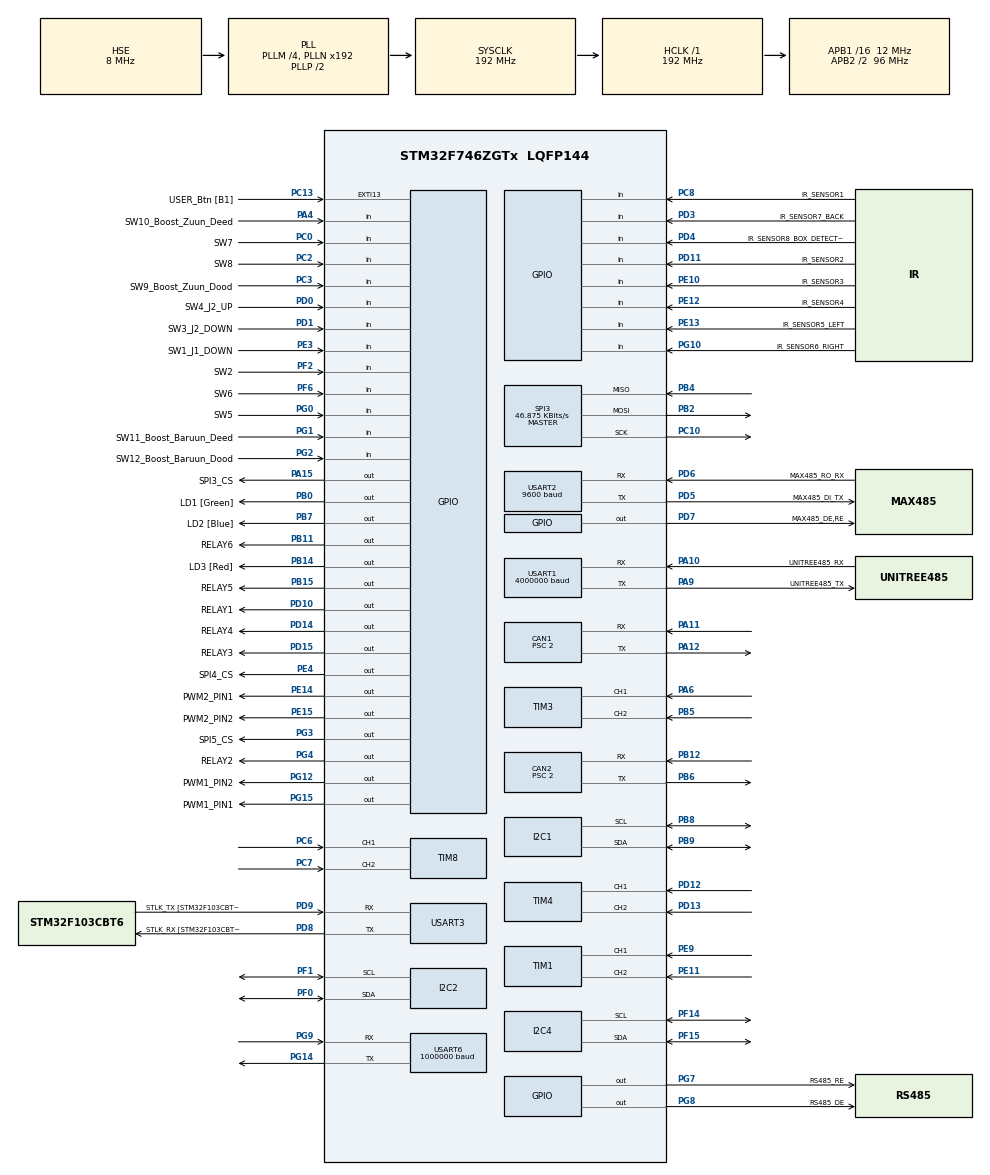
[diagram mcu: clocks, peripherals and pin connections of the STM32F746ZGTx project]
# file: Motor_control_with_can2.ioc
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CAN1.ABOM=ENABLE
CAN1.BS1=CAN_BS1_4TQ
CAN1.CalculateBaudRate=1000000
CAN1.CalculateTimeBit=1000
CAN1.CalculateTimeQuantum=166.66666666666666
CAN1.NART=ENABLE
CAN1.Prescaler=2
CAN2.ABOM=ENABLE
CAN2.BS1=CAN_BS1_4TQ
CAN2.CalculateBaudRate=1000000
CAN2.CalculateTimeBit=1000
CAN2.CalculateTimeQuantum=166.66666666666666
CAN2.NART=ENABLE
CAN2.Prescaler=2
Dma.Request0=USART2_TX
Dma.Request1=USART6_RX
Dma.Request2=USART6_TX
Dma.USART2_TX.0.Direction=DMA_MEMORY_TO_PERIPH
Dma.USART2_TX.0.FIFOMode=DMA_FIFOMODE_DISABLE
Dma.USART2_TX.0.Instance=DMA1_Stream6
Dma.USART2_TX.0.MemDataAlignment=DMA_MDATAALIGN_BYTE
Dma.USART2_TX.0.MemInc=DMA_MINC_ENABLE
Dma.USART2_TX.0.Mode=DMA_CIRCULAR
Dma.USART2_TX.0.PeriphDataAlignment=DMA_PDATAALIGN_BYTE
Dma.USART2_TX.0.PeriphInc=DMA_PINC_DISABLE
Dma.USART2_TX.0.Priority=DMA_PRIORITY_VERY_HIGH
Dma.USART6_RX.1.Direction=DMA_PERIPH_TO_MEMORY
Dma.USART6_RX.1.FIFOMode=DMA_FIFOMODE_DISABLE
Dma.USART6_RX.1.Instance=DMA2_Stream1
Dma.USART6_RX.1.MemDataAlignment=DMA_MDATAALIGN_BYTE
Dma.USART6_RX.1.MemInc=DMA_MINC_ENABLE
Dma.USART6_RX.1.Mode=DMA_NORMAL
Dma.USART6_RX.1.PeriphDataAlignment=DMA_PDATAALIGN_BYTE
Dma.USART6_RX.1.PeriphInc=DMA_PINC_DISABLE
Dma.USART6_RX.1.Priority=DMA_PRIORITY_VERY_HIGH
Dma.USART6_TX.2.Direction=DMA_MEMORY_TO_PERIPH
Dma.USART6_TX.2.FIFOMode=DMA_FIFOMODE_DISABLE
Dma.USART6_TX.2.Instance=DMA2_Stream6
Dma.USART6_TX.2.MemDataAlignment=DMA_MDATAALIGN_BYTE
Dma.USART6_TX.2.MemInc=DMA_MINC_ENABLE
Dma.USART6_TX.2.Mode=DMA_CIRCULAR
Dma.USART6_TX.2.PeriphDataAlignment=DMA_PDATAALIGN_BYTE
Dma.USART6_TX.2.PeriphInc=DMA_PINC_DISABLE
Dma.USART6_TX.2.Priority=DMA_PRIORITY_VERY_HIGH
I2C1.Timing=0x40000A0B
I2C2.Timing=0x40000A0B
I2C4.Timing=0x40000A0B
Mcu.Family=STM32F7
Mcu.Name=STM32F746ZGTx
Mcu.Package=LQFP144
NVIC.CAN1_RX0_IRQn=true\:0\:0\:false\:false\:true\:true\:true\:true
NVIC.CAN1_RX1_IRQn=true\:0\:0\:false\:false\:true\:true\:true\:true
NVIC.CAN2_RX0_IRQn=true\:0\:0\:false\:false\:true\:true\:true\:true
NVIC.CAN2_RX1_IRQn=true\:0\:0\:false\:false\:true\:true\:true\:true
NVIC.DMA1_Stream6_IRQn=true\:0\:0\:false\:false\:true\:false\:true\:true
NVIC.DMA2_Stream1_IRQn=true\:0\:0\:false\:false\:true\:false\:true\:true
NVIC.DMA2_Stream6_IRQn=true\:0\:0\:false\:false\:true\:false\:true\:true
NVIC.PriorityGroup=NVIC_PRIORITYGROUP_4
NVIC.TIM7_IRQn=true\:15\:0\:true\:false\:true\:false\:true\:true
NVIC.TimeBase=TIM7_IRQn
NVIC.TimeBaseIP=TIM7
NVIC.USART2_IRQn=true\:0\:0\:false\:false\:true\:true\:true\:true
NVIC.USART6_IRQn=true\:0\:0\:false\:false\:true\:true\:true\:true
PA10.GPIO_Label=UNITREE485_RX
PA10.Mode=Asynchronous
PA10.Signal=USART1_RX
PA11.Mode=CAN_Activate
PA11.Signal=CAN1_RX
PA12.Mode=CAN_Activate
PA12.Signal=CAN1_TX
PA13.GPIO_Label=TMS
PA13.Mode=Serial_Wire
PA13.Signal=SYS_JTMS-SWDIO
PA14.GPIO_Label=TCK
PA14.Mode=Serial_Wire
PA14.Signal=SYS_JTCK-SWCLK
PA15.GPIO_Label=SPI3_CS
PA15.GPIO_Speed=GPIO_SPEED_FREQ_LOW
PA15.Signal=GPIO_Output
PA4.GPIO_Label=SW10_Boost_Zuun_Deed
PA4.Signal=GPIO_Input
PA6.Signal=S_TIM3_CH1
PA9.GPIO_Label=UNITREE485_TX
PA9.Mode=Asynchronous
PA9.Signal=USART1_TX
PB0.GPIO_Label=LD1 [Green]
PB0.Signal=GPIO_Output
PB11.GPIO_Label=RELAY6
PB11.Signal=GPIO_Output
PB12.Mode=CAN_Activate
PB12.Signal=CAN2_RX
PB14.GPIO_Label=LD3 [Red]
PB14.Signal=GPIO_Output
PB15.GPIO_Label=RELAY5
PB15.Signal=GPIO_Output
PB2.Mode=Full_Duplex_Master
PB2.Signal=SPI3_MOSI
PB4.Mode=Full_Duplex_Master
PB4.Signal=SPI3_MISO
PB5.Signal=S_TIM3_CH2
PB6.Mode=CAN_Activate
PB6.Signal=CAN2_TX
PB7.GPIO_Label=LD2 [Blue]
PB7.Signal=GPIO_Output
PB8.Mode=I2C
PB8.Signal=I2C1_SCL
PB9.Mode=I2C
PB9.Signal=I2C1_SDA
PC0.GPIO_Label=SW7
PC0.Signal=GPIO_Input
PC10.Mode=Full_Duplex_Master
PC10.Signal=SPI3_SCK
PC13.GPIO_Label=USER_Btn [B1]
PC13.Signal=GPXTI13
PC14/OSC32_IN.Mode=LSE-External-Oscillator
PC14/OSC32_IN.Signal=RCC_OSC32_IN
PC15/OSC32_OUT.Mode=LSE-External-Oscillator
PC15/OSC32_OUT.Signal=RCC_OSC32_OUT
PC2.GPIO_Label=SW8
PC2.Signal=GPIO_Input
PC3.GPIO_Label=SW9_Boost_Zuun_Dood
PC3.Signal=GPIO_Input
PC6.Signal=S_TIM8_CH1
PC7.Signal=S_TIM8_CH2
PC8.GPIO_Label=IR_SENSOR1
PC8.Signal=GPIO_Input
PD0.GPIO_Label=SW4_J2_UP
PD0.Signal=GPIO_Input
PD1.GPIO_Label=SW3_J2_DOWN
PD1.Signal=GPIO_Input
PD10.GPIO_Label=RELAY1
PD10.Signal=GPIO_Output
PD11.GPIO_Label=IR_SENSOR2
PD11.Signal=GPIO_Input
PD12.Signal=S_TIM4_CH1
PD13.Signal=S_TIM4_CH2
PD14.GPIO_Label=RELAY4
PD14.Signal=GPIO_Output
PD15.GPIO_Label=RELAY3
PD15.Signal=GPIO_Output
PD3.GPIO_Label=IR_SENSOR7_BACK
PD3.Signal=GPIO_Input
PD4.GPIO_Label=IR_SENSOR8_BOX_DETECTION
PD4.Signal=GPIO_Input
PD5.GPIO_Label=MAX485_DI_TX
PD5.Mode=Asynchronous
PD5.Signal=USART2_TX
PD6.GPIO_Label=MAX485_RO_RX
PD6.Mode=Asynchronous
PD6.Signal=USART2_RX
PD7.GPIO_Label=MAX485_DE,RE
PD7.Signal=GPIO_Output
PD8.GPIO_Label=STLK_RX [STM32F103CBT6_PA3]
PD8.GPIO_PuPd=GPIO_PULLUP
PD8.Mode=Asynchronous
PD8.Signal=USART3_TX
PD9.GPIO_Label=STLK_TX [STM32F103CBT6_PA2]
PD9.GPIO_PuPd=GPIO_PULLUP
PD9.Mode=Asynchronous
PD9.Signal=USART3_RX
PE10.GPIO_Label=IR_SENSOR3
PE10.Signal=GPIO_Input
PE11.Signal=S_TIM1_CH2
PE12.GPIO_Label=IR_SENSOR4
PE12.Signal=GPIO_Input
PE13.GPIO_Label=IR_SENSOR5_LEFT
PE13.Signal=GPIO_Input
PE14.GPIO_Label=PWM2_PIN1
PE14.Signal=GPIO_Output
PE15.GPIO_Label=PWM2_PIN2
PE15.Signal=GPIO_Output
PE3.GPIO_Label=SW1_J1_DOWN
PE3.Signal=GPIO_Input
PE4.GPIO_Label=SPI4_CS
PE4.Signal=GPIO_Output
PE7.Signal=UART7_RX
PE9.Signal=S_TIM1_CH1
PF0.Mode=I2C
PF0.Signal=I2C2_SDA
PF1.Mode=I2C
PF1.Signal=I2C2_SCL
PF14.Mode=I2C
PF14.Signal=I2C4_SCL
PF15.Mode=I2C
PF15.Signal=I2C4_SDA
PF2.GPIO_Label=SW2
PF2.Signal=GPIO_Input
PF6.GPIO_Label=SW6
PF6.Signal=GPIO_Input
PG0.GPIO_Label=SW5
PG0.Signal=GPIO_Input
PG1.GPIO_Label=SW11_Boost_Baruun_Deed
PG1.Signal=GPIO_Input
PG10.GPIO_Label=IR_SENSOR6_RIGHT
PG10.Signal=GPIO_Input
PG12.GPIO_Label=PWM1_PIN2
PG12.Signal=GPIO_Output
PG14.Mode=Asynchronous
PG14.Signal=USART6_TX
PG15.GPIO_Label=PWM1_PIN1
PG15.Signal=GPIO_Output
PG2.GPIO_Label=SW12_Boost_Baruun_Dood
PG2.Signal=GPIO_Input
PG3.GPIO_Label=SPI5_CS
PG3.Signal=GPIO_Output
PG4.GPIO_Label=RELAY2
PG4.Signal=GPIO_Output
PG7.GPIO_Label=RS485_RE
PG7.GPIO_Speed=GPIO_SPEED_FREQ_VERY_HIGH
PG7.PinState=GPIO_PIN_SET
PG7.Signal=GPIO_Output
PG8.GPIO_Label=RS485_DE
PG8.GPIO_Speed=GPIO_SPEED_FREQ_VERY_HIGH
PG8.Signal=GPIO_Output
PG9.Mode=Asynchronous
PG9.Signal=USART6_RX
PH0/OSC_IN.GPIO_Label=MCO [STM32F103CBT6_PA8]
PH0/OSC_IN.Mode=HSE-External-Oscillator
PH0/OSC_IN.Signal=RCC_OSC_IN
PH1/OSC_OUT.Mode=HSE-External-Oscillator
PH1/OSC_OUT.Signal=RCC_OSC_OUT
ProjectManager.HeapSize=0x200
ProjectManager.StackSize=0x400
ProjectManager.TargetToolchain=STM32CubeIDE
RCC.48MHZClocksFreq_Value=24000000
RCC.AHBFreq_Value=192000000
RCC.APB1CLKDivider=RCC_HCLK_DIV16
RCC.APB1Freq_Value=12000000
RCC.APB1TimFreq_Value=24000000
RCC.APB2CLKDivider=RCC_HCLK_DIV2
RCC.APB2Freq_Value=96000000
RCC.APB2TimFreq_Value=192000000
RCC.CortexFreq_Value=192000000
RCC.HCLKFreq_Value=192000000
RCC.HSE_VALUE=8000000
RCC.HSI_VALUE=16000000
RCC.PLLM=4
RCC.PLLMUL=RCC_PLL_MUL9
RCC.PLLQ=3
RCC.PLLSourceVirtual=RCC_PLLSOURCE_HSE
RCC.PRESCALERUSB=RCC_USBCLKSOURCE_PLL_DIV1_5
RCC.SYSCLKFreq_VALUE=192000000
RCC.SYSCLKSource=RCC_SYSCLKSOURCE_PLLCLK
RCC.SYSCLKSourceVirtual=RCC_SYSCLKSOURCE_PLLCLK
RCC.USART1CLockSelection=RCC_USART1CLKSOURCE_SYSCLK
RCC.USBFreq_Value=128000000
RCC.VCOOutputFreq_Value=384000000
SH.S_TIM1_CH1.0=TIM1_CH1,Encoder_Interface
SH.S_TIM1_CH2.0=TIM1_CH2,Encoder_Interface
SH.S_TIM3_CH1.0=TIM3_CH1,Encoder_Interface
SH.S_TIM3_CH2.0=TIM3_CH2,Encoder_Interface
SH.S_TIM4_CH1.0=TIM4_CH1,Encoder_Interface
SH.S_TIM4_CH2.0=TIM4_CH2,Encoder_Interface
SH.S_TIM8_CH1.0=TIM8_CH1,Encoder_Interface
SH.S_TIM8_CH2.0=TIM8_CH2,Encoder_Interface
SPI3.BaudRatePrescaler=SPI_BAUDRATEPRESCALER_256
SPI3.CLKPhase=SPI_PHASE_2EDGE
SPI3.CLKPolarity=SPI_POLARITY_HIGH
SPI3.CalculateBaudRate=46.875 KBits/s
SPI3.DataSize=SPI_DATASIZE_8BIT
SPI3.Direction=SPI_DIRECTION_2LINES
SPI3.FirstBit=SPI_FIRSTBIT_LSB
SPI3.Mode=SPI_MODE_MASTER
SPI3.VirtualType=VM_MASTER
TIM3.EncoderMode=TIM_ENCODERMODE_TI12
TIM4.EncoderMode=TIM_ENCODERMODE_TI12
TIM8.CounterMode=TIM_COUNTERMODE_UP
TIM8.IC1Polarity=TIM_ICPOLARITY_RISING
USART1.BaudRate=4000000
USART1.VirtualMode-Asynchronous=VM_ASYNC
USART2.BaudRate=9600
USART2.VirtualMode-Asynchronous=VM_ASYNC
USART3.VirtualMode-Asynchronous=VM_ASYNC
USART6.BaudRate=1000000
USART6.VirtualMode-Asynchronous=VM_ASYNC
VP_SYS_VS_tim7.Mode=TIM7
board=NUCLEO-F746ZG

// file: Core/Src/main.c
/* USER CODE BEGIN Header */
/**
 ******************************************************************************
 * @file           : main.c
 * @brief          : Main program body
 ******************************************************************************
 * @attention
 *
 * Copyright (c) 2026 STMicroelectronics.
 * All rights reserved.
 *
 * This software is licensed under terms that can be found in the LICENSE file
 * in the root directory of this software component.
 * If no LICENSE file comes with this software, it is provided AS-IS.
 *
 ******************************************************************************
 */
/* USER CODE END Header */
#include "main.h"

/* USER CODE BEGIN Includes */
#include "stdio.h"
#include "robstride.h"
#include "motor_control.h"
#include "WEncoder_CAN.h"

/* USER CODE END Includes */

CAN_HandleTypeDef hcan1;
CAN_HandleTypeDef hcan2;

I2C_HandleTypeDef hi2c1;
I2C_HandleTypeDef hi2c2;
I2C_HandleTypeDef hi2c4;

SPI_HandleTypeDef hspi3;

TIM_HandleTypeDef htim1;
TIM_HandleTypeDef htim3;
TIM_HandleTypeDef htim4;
TIM_HandleTypeDef htim8;

UART_HandleTypeDef huart1;
UART_HandleTypeDef huart2;
UART_HandleTypeDef huart3;
UART_HandleTypeDef huart6;
DMA_HandleTypeDef hdma_usart2_tx;
DMA_HandleTypeDef hdma_usart6_rx;
DMA_HandleTypeDef hdma_usart6_tx;

/* USER CODE BEGIN PV */

volatile uint32_t g_live_cmd   = 0U;
volatile uint32_t g_live_apply = 0U;
volatile uint8_t  brake_status = 0x00U;

static RobStrideMotor *motor_brake = NULL;   /* motor0, CAN ID 0x01 */
static RobStrideMotor *motor_acc   = NULL;   /* motor1, CAN ID 0x02 */
MOTOR_send Steering_motor_cmd;
MOTOR_recv Steering_motor_fdbck;
MOTOR_send Lift_motor_cmd;
MOTOR_recv Lift_motor_fdbck;

/* ── Joystick ─────────────────────────────────────────────────────────────
 * RX[6] → brake motor   (0=min … 127=center … 255=max)
 * RX[8] → acc motor     (0=min … 127=center … 255=max)
 * ──────────────────────────────────────────────────────────────────────── */
#define JOY_CENTER          (127U)
#define JOY_DEADBAND        (10U)        /* ±10 дотор хөдлөхгүй */

#define BRAKE_POS_RELEASED  (4.00f)
#define BRAKE_POS_ENGAGED   (6.33f)
#define ACC_POS_RELEASED    (0.63f)
#define ACC_POS_ENGAGED     (-1.05f)
#define JOY_AXIS            RX[6]
#define STEER_MAX_POS    15.0f   // моторынхоо max position-д тохируул
#define STEER_MIN_POS   -15.0f
#define JOY_STEER       RX[7]
float pos=0.6;

/* ── Briter Wire Encoder тохиргоо ──────────────────────────────────────────
 *  Encoder 0 (index 0): CAN ID=0x01, range=500mm  (50cm)
 *  Encoder 1 (index 1): CAN ID=0x02, range=4000mm (400cm)
 * ────────────────────────────────────────────────────────────────────────── */
#define ENC0_CAN_ID        0x01U
#define ENC0_RESOLUTION_MM 0.0244f   /* BRT38 500mm,  4096PPR */
#define ENC0_TOTAL_COUNTS  20491     /* 500mm / 0.0244mm      */
#define ENC0_MAX_STEP      2000      /* spike filter          */
#define ENC0_LABEL         "Enc50cm"

#define ENC1_CAN_ID        0x02U
#define ENC1_RESOLUTION_MM 0.0610f   /* BRT38 4000mm, 4096PPR */
#define ENC1_TOTAL_COUNTS  65573     /* 4000mm / 0.061mm      */
#define ENC1_MAX_STEP      5000
#define ENC1_LABEL         "Enc400cm"

/* Гаднаас ашиглах глобал утгууд */
float g_enc0_disp_mm = 0.0f;   /* 50cm  encoder displacement */
float g_enc1_disp_mm = 0.0f;   /* 400cm encoder displacement */
/* USER CODE END PV */

void SystemClock_Config(void);
static void MX_GPIO_Init(void);
static void MX_DMA_Init(void);
static void MX_I2C1_Init(void);
static void MX_USART3_UART_Init(void);
static void MX_CAN1_Init(void);
static void MX_I2C2_Init(void);
static void MX_SPI3_Init(void);
static void MX_TIM1_Init(void);
static void MX_TIM3_Init(void);
static void MX_TIM4_Init(void);
static void MX_TIM8_Init(void);
static void MX_USART1_UART_Init(void);
static void MX_USART2_UART_Init(void);
static void MX_I2C4_Init(void);
static void MX_USART6_UART_Init(void);
static void MX_CAN2_Init(void);
/* USER CODE BEGIN PFP */

static void Encoder_CAN2_Init(void);
/* USER CODE END PFP */

/* USER CODE BEGIN 0 */

uint8_t TX[9] = {0x01,0x42, 0x00, 0x00, 0x00, 0x00, 0x00, 0x00, 0x00};
uint8_t  RX[9];

/* printf → UART3 (115200 baud, USB-Serial) */
int __io_putchar(int ch)
{
    uint8_t c = (uint8_t)ch;
    (void)HAL_UART_Transmit(&huart3, &c, 1U, 2U);
    return ch;
}

static void Receive_JoyStick_Data(void)
{
	GPIOA->BSRR = (uint32_t)GPIO_PIN_15 << 16U;
	HAL_SPI_TransmitReceive(&hspi3, TX, RX, 9U, 10U);
	GPIOA->BSRR = GPIO_PIN_15;
}
/**
 * @brief  0–255 joystick утгыг float позиц руу шугаман хөрвүүлэх.
 *         127 = төв (deadband дотор) → pos_center буцаана.
 *         0   = pos_low,  255 = pos_high
 */
/*
 * @brief  0.0–1.0 хэмжилтийг pos_released → pos_engaged хооронд хөрвүүлэх
 */
static float lerp(float t, float from, float to)
{
	return from + t * (to - from);
}

/**
 * @brief  Joystick нэг тэнхлэгийг acc/brake хоёр мотор руу хуваарилах.
 *
 *  raw > center+deadband  →  Acc дарна (t=0→1),  Brake бүрэн тавина
 *  raw < center-deadband  →  Brake дарна (t=0→1), Acc бүрэн тавина
 *  deadband дотор         →  Хоёулан тавина
 */
static void apply_joystick(uint8_t raw)
{
    /* ── Acc / Brake: RX[6] ─────────────────────── */
    float acc_pos, brake_pos;

    if (raw < (JOY_CENTER - JOY_DEADBAND))
    {
        float t = (float)((JOY_CENTER - JOY_DEADBAND) - raw) /
                  (float)(JOY_CENTER - JOY_DEADBAND);
        acc_pos   = lerp(t, ACC_POS_RELEASED, ACC_POS_ENGAGED);
        brake_pos = BRAKE_POS_RELEASED;
    }
    else if (raw > (JOY_CENTER + JOY_DEADBAND))
    {
        float t = (float)(raw - (JOY_CENTER + JOY_DEADBAND)) /
                  (float)(255U - (JOY_CENTER + JOY_DEADBAND));
        brake_pos = lerp(t, BRAKE_POS_RELEASED, BRAKE_POS_ENGAGED);
        acc_pos   = ACC_POS_RELEASED;
    }
    else
    {
        acc_pos   = ACC_POS_RELEASED;
        brake_pos = BRAKE_POS_RELEASED;
    }

    (void)RobStride_WriteFloat(motor_acc,   ROBSTRIDE_IDX_LOC_REF, acc_pos);
    (void)RobStride_WriteFloat(motor_brake, ROBSTRIDE_IDX_LOC_REF, brake_pos);

    /* ── Steering: RX[7] ───────────────────────── */
    int16_t steer_raw = (int16_t)JOY_STEER - 127;

    if (steer_raw > -10 && steer_raw < 10)
    {
        steer_raw = 0;
    }

    float steer_pos = (float)steer_raw * (STEER_MAX_POS / 127.0f);

    Steering_motor_cmd.K_P = 0.1f;
    Steering_motor_cmd.K_W = 0.02f;
    Steering_motor_cmd.Pos = steer_pos;
    SERVO_Send_recv(&Steering_motor_cmd, &Steering_motor_fdbck);
}
static void motor_init(RobStrideMotor *m)
{
	(void)RobStride_ReadParam(m, ROBSTRIDE_IDX_VBUS);   HAL_Delay(50U);
	RobStride_ProcessRx();
	(void)RobStride_EnableActiveReport(m, 10U);          HAL_Delay(50U);
	RobStride_ReadAllParams(m);                          HAL_Delay(50U);
	RobStride_ProcessRx();
	(void)RobStride_Stop(m, 1U);                         HAL_Delay(100U);
	(void)RobStride_WriteU8(m, ROBSTRIDE_IDX_RUN_MODE, ROBSTRIDE_MODE_PP_POS); HAL_Delay(50U);
	(void)RobStride_Enable(m);                           HAL_Delay(100U);
	(void)RobStride_WriteFloat(m, ROBSTRIDE_IDX_LIMIT_TRQ, 15.0f); HAL_Delay(20U);
	(void)RobStride_WriteFloat(m, ROBSTRIDE_IDX_VEL_MAX,   10.0f); HAL_Delay(20U);
	(void)RobStride_WriteFloat(m, ROBSTRIDE_IDX_ACC_SET,    3.0f); HAL_Delay(20U);
}
static void Encoder_CAN2_Init(void)
{
    WEncoder_CAN_Init(&hcan2);

    /* Index 0 — CAN ID 0x01, 500mm (50cm) */
    WEncoder_CAN_AddEncoder(ENC0_CAN_ID, ENC0_LABEL,
                             ENC0_TOTAL_COUNTS, ENC0_RESOLUTION_MM, ENC0_MAX_STEP);

    /* Index 1 — CAN ID 0x02, 4000mm (400cm) */
    WEncoder_CAN_AddEncoder(ENC1_CAN_ID, ENC1_LABEL,
                             ENC1_TOTAL_COUNTS, ENC1_RESOLUTION_MM, ENC1_MAX_STEP);

    if (WEncoder_CAN_FilterStart() != HAL_OK) {
        Error_Handler();
    }
}

/* USER CODE BEGIN 4 */
void HAL_CAN_RxFifo0MsgPendingCallback(CAN_HandleTypeDef *hcan)
{
    if (hcan->Instance == CAN2) {
        WEncoder_CAN_RxCallback(hcan);
    }
}
/* ── Encoder poll + утга шинэчлэх ────────────────────────────────────────── */
static void Encoder_Poll_And_Log(void)
{
    static uint32_t log_at = 0U;
    WEnc_Reading_t enc;

    WEncoder_CAN_Poll();

    /* Encoder 0 — 50cm */
    if (WEncoder_CAN_GetByIndex(0U, &enc) && enc.valid) {
        g_enc0_disp_mm = enc.disp_mm;
    }

    /* Encoder 1 — 400cm */
    if (WEncoder_CAN_GetByIndex(1U, &enc) && enc.valid) {
        g_enc1_disp_mm = enc.disp_mm;
    }

    /* 200ms тутамд UART log */
    if ((HAL_GetTick() - log_at) >= 200U) {
        printf("[ENC0  50cm] disp=%7.2f mm | [ENC1 400cm] disp=%7.2f mm\r\n",
               (double)g_enc0_disp_mm,
               (double)g_enc1_disp_mm);
        log_at = HAL_GetTick();
    }
}
/* USER CODE END 4 */

int main(void)
{
  HAL_Init();
  SystemClock_Config();
  MX_GPIO_Init();
  MX_DMA_Init();
  MX_I2C1_Init();
  MX_USART3_UART_Init();
  MX_CAN1_Init();
  MX_I2C2_Init();
  MX_SPI3_Init();
  MX_TIM1_Init();
  MX_TIM3_Init();
  MX_TIM4_Init();
  MX_TIM8_Init();
  MX_USART1_UART_Init();
  MX_USART2_UART_Init();
  MX_I2C4_Init();
  MX_USART6_UART_Init();
  MX_CAN2_Init();

  /* USER CODE BEGIN 2 */
  Encoder_CAN2_Init();

  Steering_motor_cmd.id  = 1;
  Steering_motor_cmd.mode = 1;
  Lift_motor_cmd.id      = 3;
  Lift_motor_cmd.mode    = 1;
  RobStride_AddMotor(0xFDU, 0x01U);
  RobStride_AddMotor(0xFDU, 0x02U);
  motor_brake = &g_motors[0];
  motor_acc   = &g_motors[1];
  motor_init(motor_brake);
  motor_init(motor_acc);
  (void)RobStride_WriteFloat(motor_brake, ROBSTRIDE_IDX_LOC_REF, BRAKE_POS_RELEASED);
  (void)RobStride_WriteFloat(motor_acc,   ROBSTRIDE_IDX_LOC_REF, ACC_POS_RELEASED);
  HAL_Delay(500U);
  /* USER CODE END 2 */

  while (1)
  {
    /* USER CODE BEGIN 3 */

    /* ── Emergency stop ────────────────────────────────────────────────── */
    if (HAL_GPIO_ReadPin(SW2_GPIO_Port, SW2_Pin) == GPIO_PIN_RESET) {
        (void)RobStride_WriteFloat(motor_brake, ROBSTRIDE_IDX_LOC_REF, BRAKE_POS_ENGAGED);
        (void)RobStride_WriteFloat(motor_acc,   ROBSTRIDE_IDX_LOC_REF, ACC_POS_RELEASED);
        RobStride_ProcessRx();
        Encoder_Poll_And_Log();   /* stop үед ч encoder poll үргэлжилнэ */
        HAL_Delay(10U);
        continue;
    }

    /* ── Lift motor ─────────────────────────────────────────────────────── */
    if (RX[4] == 239) {
        Lift_motor_cmd.K_P = 0.2f; Lift_motor_cmd.Pos = 6.5f;  Lift_motor_cmd.K_W = 0.02f;
        SERVO_Send_recv(&Lift_motor_cmd, &Lift_motor_fdbck);
    } else if (RX[4] == 191) {
        Lift_motor_cmd.K_P = 0.2f; Lift_motor_cmd.Pos = -2.5f; Lift_motor_cmd.K_W = 0.02f;
        SERVO_Send_recv(&Lift_motor_cmd, &Lift_motor_fdbck);
    } else {
        Lift_motor_cmd.K_P = 0.2f; Lift_motor_cmd.Pos = 1.6f;  Lift_motor_cmd.K_W = 0.02f;
        SERVO_Send_recv(&Lift_motor_cmd, &Lift_motor_fdbck);
    }

    /* ── Encoder poll (CAN2) ────────────────────────────────────────────── */
    Encoder_Poll_And_Log();
    /*
     * Энд ашиглах:
     *   g_enc0_disp_mm  — 50cm  encoder displacement (mm)
     *   g_enc1_disp_mm  — 400cm encoder displacement (mm)
     *
     * Жишээ:
     *   if (g_enc0_disp_mm > 300.0f) { ... }   // 30cm хэтэрвэл
     *   if (g_enc1_disp_mm > 2000.0f) { ... }  // 200cm хэтэрвэл
     */

    /* ── Joystick + motors ──────────────────────────────────────────────── */
    Receive_JoyStick_Data();
    apply_joystick(JOY_AXIS);
    RobStride_ProcessRx();

    HAL_Delay(10U);
  }
  /* USER CODE END 3 */
}
void SystemClock_Config(void)
{
  RCC_OscInitTypeDef RCC_OscInitStruct = {0};
  RCC_ClkInitTypeDef RCC_ClkInitStruct = {0};

  /** Configure LSE Drive Capability
  */
  HAL_PWR_EnableBkUpAccess();

  /** Configure the main internal regulator output voltage
  */
  __HAL_RCC_PWR_CLK_ENABLE();
  __HAL_PWR_VOLTAGESCALING_CONFIG(PWR_REGULATOR_VOLTAGE_SCALE1);

  /** Initializes the RCC Oscillators according to the specified parameters
  * in the RCC_OscInitTypeDef structure.
  */
  RCC_OscInitStruct.OscillatorType = RCC_OSCILLATORTYPE_HSE;
  RCC_OscInitStruct.HSEState = RCC_HSE_ON;
  RCC_OscInitStruct.PLL.PLLState = RCC_PLL_ON;
  RCC_OscInitStruct.PLL.PLLSource = RCC_PLLSOURCE_HSE;
  RCC_OscInitStruct.PLL.PLLM = 4;
  RCC_OscInitStruct.PLL.PLLN = 192;
  RCC_OscInitStruct.PLL.PLLP = RCC_PLLP_DIV2;
  RCC_OscInitStruct.PLL.PLLQ = 3;
  if (HAL_RCC_OscConfig(&RCC_OscInitStruct) != HAL_OK)
  {
    Error_Handler();
  }

  /** Activate the Over-Drive mode
  */
  if (HAL_PWREx_EnableOverDrive() != HAL_OK)
  {
    Error_Handler();
  }

  /** Initializes the CPU, AHB and APB buses clocks
  */
  RCC_ClkInitStruct.ClockType = RCC_CLOCKTYPE_HCLK|RCC_CLOCKTYPE_SYSCLK
                              |RCC_CLOCKTYPE_PCLK1|RCC_CLOCKTYPE_PCLK2;
  RCC_ClkInitStruct.SYSCLKSource = RCC_SYSCLKSOURCE_PLLCLK;
  RCC_ClkInitStruct.AHBCLKDivider = RCC_SYSCLK_DIV1;
  RCC_ClkInitStruct.APB1CLKDivider = RCC_HCLK_DIV16;
  RCC_ClkInitStruct.APB2CLKDivider = RCC_HCLK_DIV2;

  if (HAL_RCC_ClockConfig(&RCC_ClkInitStruct, FLASH_LATENCY_6) != HAL_OK)
  {
    Error_Handler();
  }
}

static void MX_CAN1_Init(void)
{

  hcan1.Instance = CAN1;
  hcan1.Init.Prescaler = 2;
  hcan1.Init.Mode = CAN_MODE_NORMAL;
  hcan1.Init.SyncJumpWidth = CAN_SJW_1TQ;
  hcan1.Init.TimeSeg1 = CAN_BS1_4TQ;
  hcan1.Init.TimeSeg2 = CAN_BS2_1TQ;
  hcan1.Init.TimeTriggeredMode = DISABLE;
  hcan1.Init.AutoBusOff = ENABLE;
  hcan1.Init.AutoWakeUp = DISABLE;
  hcan1.Init.AutoRetransmission = ENABLE;
  hcan1.Init.ReceiveFifoLocked = DISABLE;
  hcan1.Init.TransmitFifoPriority = DISABLE;
  if (HAL_CAN_Init(&hcan1) != HAL_OK)
  {
    Error_Handler();
  }
  /* USER CODE BEGIN CAN1_Init 2 */
	{
		CAN_FilterTypeDef can_filter = {0};
		can_filter.FilterBank = 0;
		can_filter.FilterMode = CAN_FILTERMODE_IDMASK;
		can_filter.FilterScale = CAN_FILTERSCALE_32BIT;
		can_filter.FilterIdHigh = 0x0000;
		can_filter.FilterIdLow = 0x0000;
		can_filter.FilterMaskIdHigh = 0x0000;
		can_filter.FilterMaskIdLow = 0x0000;
		can_filter.FilterFIFOAssignment = CAN_RX_FIFO0;
		can_filter.FilterActivation = ENABLE;
		can_filter.SlaveStartFilterBank = 14;
		if (HAL_CAN_ConfigFilter(&hcan1, &can_filter) != HAL_OK)
		{
			Error_Handler();
		}
		if (HAL_CAN_Start(&hcan1) != HAL_OK)
		{
			Error_Handler();
		}
	}

  /* USER CODE END CAN1_Init 2 */

}

static void MX_CAN2_Init(void)
{

  hcan2.Instance = CAN2;
  hcan2.Init.Prescaler = 2;
  hcan2.Init.Mode = CAN_MODE_NORMAL;
  hcan2.Init.SyncJumpWidth = CAN_SJW_1TQ;
  hcan2.Init.TimeSeg1 = CAN_BS1_4TQ;
  hcan2.Init.TimeSeg2 = CAN_BS2_1TQ;
  hcan2.Init.TimeTriggeredMode = DISABLE;
  hcan2.Init.AutoBusOff = ENABLE;
  hcan2.Init.AutoWakeUp = DISABLE;
  hcan2.Init.AutoRetransmission = ENABLE;
  hcan2.Init.ReceiveFifoLocked = DISABLE;
  hcan2.Init.TransmitFifoPriority = DISABLE;
  if (HAL_CAN_Init(&hcan2) != HAL_OK)
  {
    Error_Handler();
  }

}

static void MX_I2C1_Init(void)
{

  hi2c1.Instance = I2C1;
  hi2c1.Init.Timing = 0x40000A0B;
  hi2c1.Init.OwnAddress1 = 0;
  hi2c1.Init.AddressingMode = I2C_ADDRESSINGMODE_7BIT;
  hi2c1.Init.DualAddressMode = I2C_DUALADDRESS_DISABLE;
  hi2c1.Init.OwnAddress2 = 0;
  hi2c1.Init.OwnAddress2Masks = I2C_OA2_NOMASK;
  hi2c1.Init.GeneralCallMode = I2C_GENERALCALL_DISABLE;
  hi2c1.Init.NoStretchMode = I2C_NOSTRETCH_DISABLE;
  if (HAL_I2C_Init(&hi2c1) != HAL_OK)
  {
    Error_Handler();
  }

  /** Configure Analogue filter
  */
  if (HAL_I2CEx_ConfigAnalogFilter(&hi2c1, I2C_ANALOGFILTER_ENABLE) != HAL_OK)
  {
    Error_Handler();
  }

  /** Configure Digital filter
  */
  if (HAL_I2CEx_ConfigDigitalFilter(&hi2c1, 0) != HAL_OK)
  {
    Error_Handler();
  }

}

static void MX_I2C2_Init(void)
{

  hi2c2.Instance = I2C2;
  hi2c2.Init.Timing = 0x40000A0B;
  hi2c2.Init.OwnAddress1 = 0;
  hi2c2.Init.AddressingMode = I2C_ADDRESSINGMODE_7BIT;
  hi2c2.Init.DualAddressMode = I2C_DUALADDRESS_DISABLE;
  hi2c2.Init.OwnAddress2 = 0;
  hi2c2.Init.OwnAddress2Masks = I2C_OA2_NOMASK;
  hi2c2.Init.GeneralCallMode = I2C_GENERALCALL_DISABLE;
  hi2c2.Init.NoStretchMode = I2C_NOSTRETCH_DISABLE;
  if (HAL_I2C_Init(&hi2c2) != HAL_OK)
  {
    Error_Handler();
  }

  /** Configure Analogue filter
  */
  if (HAL_I2CEx_ConfigAnalogFilter(&hi2c2, I2C_ANALOGFILTER_ENABLE) != HAL_OK)
  {
    Error_Handler();
  }

  /** Configure Digital filter
  */
  if (HAL_I2CEx_ConfigDigitalFilter(&hi2c2, 0) != HAL_OK)
  {
    Error_Handler();
  }

}

static void MX_I2C4_Init(void)
{

  hi2c4.Instance = I2C4;
  hi2c4.Init.Timing = 0x40000A0B;
  hi2c4.Init.OwnAddress1 = 0;
  hi2c4.Init.AddressingMode = I2C_ADDRESSINGMODE_7BIT;
  hi2c4.Init.DualAddressMode = I2C_DUALADDRESS_DISABLE;
  hi2c4.Init.OwnAddress2 = 0;
  hi2c4.Init.OwnAddress2Masks = I2C_OA2_NOMASK;
  hi2c4.Init.GeneralCallMode = I2C_GENERALCALL_DISABLE;
  hi2c4.Init.NoStretchMode = I2C_NOSTRETCH_DISABLE;
  if (HAL_I2C_Init(&hi2c4) != HAL_OK)
  {
    Error_Handler();
  }

  /** Configure Analogue filter
  */
  if (HAL_I2CEx_ConfigAnalogFilter(&hi2c4, I2C_ANALOGFILTER_ENABLE) != HAL_OK)
  {
    Error_Handler();
  }

  /** Configure Digital filter
  */
  if (HAL_I2CEx_ConfigDigitalFilter(&hi2c4, 0) != HAL_OK)
  {
    Error_Handler();
  }

}

static void MX_SPI3_Init(void)
{

  /* SPI3 parameter configuration*/
  hspi3.Instance = SPI3;
  hspi3.Init.Mode = SPI_MODE_MASTER;
  hspi3.Init.Direction = SPI_DIRECTION_2LINES;
  hspi3.Init.DataSize = SPI_DATASIZE_8BIT;
  hspi3.Init.CLKPolarity = SPI_POLARITY_HIGH;
  hspi3.Init.CLKPhase = SPI_PHASE_2EDGE;
  hspi3.Init.NSS = SPI_NSS_SOFT;
  hspi3.Init.BaudRatePrescaler = SPI_BAUDRATEPRESCALER_256;
  hspi3.Init.FirstBit = SPI_FIRSTBIT_LSB;
  hspi3.Init.TIMode = SPI_TIMODE_DISABLE;
  hspi3.Init.CRCCalculation = SPI_CRCCALCULATION_DISABLE;
  hspi3.Init.CRCPolynomial = 7;
  hspi3.Init.CRCLength = SPI_CRC_LENGTH_DATASIZE;
  hspi3.Init.NSSPMode = SPI_NSS_PULSE_DISABLE;
  if (HAL_SPI_Init(&hspi3) != HAL_OK)
  {
    Error_Handler();
  }

}

static void MX_TIM1_Init(void)
{

  TIM_Encoder_InitTypeDef sConfig = {0};
  TIM_MasterConfigTypeDef sMasterConfig = {0};

  htim1.Instance = TIM1;
  htim1.Init.Prescaler = 0;
  htim1.Init.CounterMode = TIM_COUNTERMODE_UP;
  htim1.Init.Period = 65535;
  htim1.Init.ClockDivision = TIM_CLOCKDIVISION_DIV1;
  htim1.Init.RepetitionCounter = 0;
  htim1.Init.AutoReloadPreload = TIM_AUTORELOAD_PRELOAD_DISABLE;
  sConfig.EncoderMode = TIM_ENCODERMODE_TI1;
  sConfig.IC1Polarity = TIM_ICPOLARITY_RISING;
  sConfig.IC1Selection = TIM_ICSELECTION_DIRECTTI;
  sConfig.IC1Prescaler = TIM_ICPSC_DIV1;
  sConfig.IC1Filter = 0;
  sConfig.IC2Polarity = TIM_ICPOLARITY_RISING;
  sConfig.IC2Selection = TIM_ICSELECTION_DIRECTTI;
  sConfig.IC2Prescaler = TIM_ICPSC_DIV1;
  sConfig.IC2Filter = 0;
  if (HAL_TIM_Encoder_Init(&htim1, &sConfig) != HAL_OK)
  {
    Error_Handler();
  }
  sMasterConfig.MasterOutputTrigger = TIM_TRGO_RESET;
  sMasterConfig.MasterOutputTrigger2 = TIM_TRGO2_RESET;
  sMasterConfig.MasterSlaveMode = TIM_MASTERSLAVEMODE_DISABLE;
  if (HAL_TIMEx_MasterConfigSynchronization(&htim1, &sMasterConfig) != HAL_OK)
  {
    Error_Handler();
  }

}

static void MX_TIM3_Init(void)
{

  TIM_Encoder_InitTypeDef sConfig = {0};
  TIM_MasterConfigTypeDef sMasterConfig = {0};

  htim3.Instance = TIM3;
  htim3.Init.Prescaler = 0;
  htim3.Init.CounterMode = TIM_COUNTERMODE_UP;
  htim3.Init.Period = 65535;
  htim3.Init.ClockDivision = TIM_CLOCKDIVISION_DIV1;
  htim3.Init.AutoReloadPreload = TIM_AUTORELOAD_PRELOAD_DISABLE;
  sConfig.EncoderMode = TIM_ENCODERMODE_TI12;
  sConfig.IC1Polarity = TIM_ICPOLARITY_RISING;
  sConfig.IC1Selection = TIM_ICSELECTION_DIRECTTI;
  sConfig.IC1Prescaler = TIM_ICPSC_DIV1;
  sConfig.IC1Filter = 0;
  sConfig.IC2Polarity = TIM_ICPOLARITY_RISING;
  sConfig.IC2Selection = TIM_ICSELECTION_DIRECTTI;
  sConfig.IC2Prescaler = TIM_ICPSC_DIV1;
  sConfig.IC2Filter = 0;
  if (HAL_TIM_Encoder_Init(&htim3, &sConfig) != HAL_OK)
  {
    Error_Handler();
  }
  sMasterConfig.MasterOutputTrigger = TIM_TRGO_RESET;
  sMasterConfig.MasterSlaveMode = TIM_MASTERSLAVEMODE_DISABLE;
  if (HAL_TIMEx_MasterConfigSynchronization(&htim3, &sMasterConfig) != HAL_OK)
  {
    Error_Handler();
  }

}

static void MX_TIM4_Init(void)
{

  TIM_Encoder_InitTypeDef sConfig = {0};
  TIM_MasterConfigTypeDef sMasterConfig = {0};

  htim4.Instance = TIM4;
  htim4.Init.Prescaler = 0;
  htim4.Init.CounterMode = TIM_COUNTERMODE_UP;
  htim4.Init.Period = 65535;
  htim4.Init.ClockDivision = TIM_CLOCKDIVISION_DIV1;
  htim4.Init.AutoReloadPreload = TIM_AUTORELOAD_PRELOAD_DISABLE;
  sConfig.EncoderMode = TIM_ENCODERMODE_TI12;
  sConfig.IC1Polarity = TIM_ICPOLARITY_RISING;
  sConfig.IC1Selection = TIM_ICSELECTION_DIRECTTI;
  sConfig.IC1Prescaler = TIM_ICPSC_DIV1;
  sConfig.IC1Filter = 0;
  sConfig.IC2Polarity = TIM_ICPOLARITY_RISING;
  sConfig.IC2Selection = TIM_ICSELECTION_DIRECTTI;
  sConfig.IC2Prescaler = TIM_ICPSC_DIV1;
  sConfig.IC2Filter = 0;
  if (HAL_TIM_Encoder_Init(&htim4, &sConfig) != HAL_OK)
  {
    Error_Handler();
  }
  sMasterConfig.MasterOutputTrigger = TIM_TRGO_RESET;
  sMasterConfig.MasterSlaveMode = TIM_MASTERSLAVEMODE_DISABLE;
  if (HAL_TIMEx_MasterConfigSynchronization(&htim4, &sMasterConfig) != HAL_OK)
  {
    Error_Handler();
  }

}

static void MX_TIM8_Init(void)
{

  TIM_Encoder_InitTypeDef sConfig = {0};
  TIM_MasterConfigTypeDef sMasterConfig = {0};

  htim8.Instance = TIM8;
  htim8.Init.Prescaler = 0;
  htim8.Init.CounterMode = TIM_COUNTERMODE_UP;
  htim8.Init.Period = 65535;
  htim8.Init.ClockDivision = TIM_CLOCKDIVISION_DIV1;
  htim8.Init.RepetitionCounter = 0;
  htim8.Init.AutoReloadPreload = TIM_AUTORELOAD_PRELOAD_DISABLE;
  sConfig.EncoderMode = TIM_ENCODERMODE_TI1;
  sConfig.IC1Polarity = TIM_ICPOLARITY_RISING;
  sConfig.IC1Selection = TIM_ICSELECTION_DIRECTTI;
  sConfig.IC1Prescaler = TIM_ICPSC_DIV1;
  sConfig.IC1Filter = 0;
  sConfig.IC2Polarity = TIM_ICPOLARITY_RISING;
  sConfig.IC2Selection = TIM_ICSELECTION_DIRECTTI;
  sConfig.IC2Prescaler = TIM_ICPSC_DIV1;
  sConfig.IC2Filter = 0;
  if (HAL_TIM_Encoder_Init(&htim8, &sConfig) != HAL_OK)
  {
    Error_Handler();
  }
  sMasterConfig.MasterOutputTrigger = TIM_TRGO_RESET;
  sMasterConfig.MasterOutputTrigger2 = TIM_TRGO2_RESET;
  sMasterConfig.MasterSlaveMode = TIM_MASTERSLAVEMODE_DISABLE;
  if (HAL_TIMEx_MasterConfigSynchronization(&htim8, &sMasterConfig) != HAL_OK)
  {
    Error_Handler();
  }

}

static void MX_USART1_UART_Init(void)
{

  huart1.Instance = USART1;
  huart1.Init.BaudRate = 4000000;
  huart1.Init.WordLength = UART_WORDLENGTH_8B;
  huart1.Init.StopBits = UART_STOPBITS_1;
  huart1.Init.Parity = UART_PARITY_NONE;
  huart1.Init.Mode = UART_MODE_TX_RX;
  huart1.Init.HwFlowCtl = UART_HWCONTROL_NONE;
  huart1.Init.OverSampling = UART_OVERSAMPLING_16;
  huart1.Init.OneBitSampling = UART_ONE_BIT_SAMPLE_DISABLE;
  huart1.AdvancedInit.AdvFeatureInit = UART_ADVFEATURE_NO_INIT;
  if (HAL_UART_Init(&huart1) != HAL_OK)
  {
    Error_Handler();
  }

}

static void MX_USART2_UART_Init(void)
{

  huart2.Instance = USART2;
  huart2.Init.BaudRate = 9600;
  huart2.Init.WordLength = UART_WORDLENGTH_8B;
  huart2.Init.StopBits = UART_STOPBITS_1;
  huart2.Init.Parity = UART_PARITY_NONE;
  huart2.Init.Mode = UART_MODE_TX_RX;
  huart2.Init.HwFlowCtl = UART_HWCONTROL_NONE;
  huart2.Init.OverSampling = UART_OVERSAMPLING_16;
  huart2.Init.OneBitSampling = UART_ONE_BIT_SAMPLE_DISABLE;
  huart2.AdvancedInit.AdvFeatureInit = UART_ADVFEATURE_NO_INIT;
  if (HAL_UART_Init(&huart2) != HAL_OK)
  {
    Error_Handler();
  }

}

static void MX_USART3_UART_Init(void)
{

  huart3.Instance = USART3;
  huart3.Init.BaudRate = 115200;
  huart3.Init.WordLength = UART_WORDLENGTH_8B;
  huart3.Init.StopBits = UART_STOPBITS_1;
  huart3.Init.Parity = UART_PARITY_NONE;
  huart3.Init.Mode = UART_MODE_TX_RX;
  huart3.Init.HwFlowCtl = UART_HWCONTROL_NONE;
  huart3.Init.OverSampling = UART_OVERSAMPLING_16;
  huart3.Init.OneBitSampling = UART_ONE_BIT_SAMPLE_DISABLE;
  huart3.AdvancedInit.AdvFeatureInit = UART_ADVFEATURE_NO_INIT;
  if (HAL_UART_Init(&huart3) != HAL_OK)
  {
    Error_Handler();
  }

}

static void MX_USART6_UART_Init(void)
{

  huart6.Instance = USART6;
  huart6.Init.BaudRate = 1000000;
  huart6.Init.WordLength = UART_WORDLENGTH_8B;
  huart6.Init.StopBits = UART_STOPBITS_1;
  huart6.Init.Parity = UART_PARITY_NONE;
  huart6.Init.Mode = UART_MODE_TX_RX;
  huart6.Init.HwFlowCtl = UART_HWCONTROL_NONE;
  huart6.Init.OverSampling = UART_OVERSAMPLING_16;
  huart6.Init.OneBitSampling = UART_ONE_BIT_SAMPLE_DISABLE;
  huart6.AdvancedInit.AdvFeatureInit = UART_ADVFEATURE_NO_INIT;
  if (HAL_UART_Init(&huart6) != HAL_OK)
  {
    Error_Handler();
  }

}

static void MX_DMA_Init(void)
{

  /* DMA controller clock enable */
  __HAL_RCC_DMA1_CLK_ENABLE();
  __HAL_RCC_DMA2_CLK_ENABLE();

  /* DMA interrupt init */
  /* DMA1_Stream6_IRQn interrupt configuration */
  HAL_NVIC_SetPriority(DMA1_Stream6_IRQn, 0, 0);
  HAL_NVIC_EnableIRQ(DMA1_Stream6_IRQn);
  /* DMA2_Stream1_IRQn interrupt configuration */
  HAL_NVIC_SetPriority(DMA2_Stream1_IRQn, 0, 0);
  HAL_NVIC_EnableIRQ(DMA2_Stream1_IRQn);
  /* DMA2_Stream6_IRQn interrupt configuration */
  HAL_NVIC_SetPriority(DMA2_Stream6_IRQn, 0, 0);
  HAL_NVIC_EnableIRQ(DMA2_Stream6_IRQn);

}

static void MX_GPIO_Init(void)
{
  GPIO_InitTypeDef GPIO_InitStruct = {0};

  /* GPIO Ports Clock Enable */
  __HAL_RCC_GPIOE_CLK_ENABLE();
  __HAL_RCC_GPIOC_CLK_ENABLE();
  __HAL_RCC_GPIOF_CLK_ENABLE();
  __HAL_RCC_GPIOH_CLK_ENABLE();
  __HAL_RCC_GPIOA_CLK_ENABLE();
  __HAL_RCC_GPIOB_CLK_ENABLE();
  __HAL_RCC_GPIOG_CLK_ENABLE();
  __HAL_RCC_GPIOD_CLK_ENABLE();

  /*Configure GPIO pin Output Level */
  HAL_GPIO_WritePin(GPIOE, SPI4_CS_Pin|PWM2_PIN1_Pin|PWM2_PIN2_Pin, GPIO_PIN_RESET);

  /*Configure GPIO pin Output Level */
  HAL_GPIO_WritePin(GPIOB, LD1_Pin|RELAY6_Pin|LD3_Pin|RELAY5_Pin
                          |LD2_Pin, GPIO_PIN_RESET);

  /*Configure GPIO pin Output Level */
  HAL_GPIO_WritePin(GPIOD, RELAY1_Pin|RELAY4_Pin|RELAY3_Pin|MAX485_DE_RE_Pin, GPIO_PIN_RESET);

  /*Configure GPIO pin Output Level */
  HAL_GPIO_WritePin(GPIOG, SPI5_CS_Pin|RELAY2_Pin|RS485_DE_Pin|PWM1_PIN2_Pin
                          |PWM1_PIN1_Pin, GPIO_PIN_RESET);

  /*Configure GPIO pin Output Level */
  HAL_GPIO_WritePin(RS485_RE_GPIO_Port, RS485_RE_Pin, GPIO_PIN_SET);

  /*Configure GPIO pin Output Level */
  HAL_GPIO_WritePin(SPI3_CS_GPIO_Port, SPI3_CS_Pin, GPIO_PIN_RESET);

  /*Configure GPIO pins : SW1_J1_DOWN_Pin IR_SENSOR3_Pin IR_SENSOR4_Pin IR_SENSOR5_LEFT_Pin */
  GPIO_InitStruct.Pin = SW1_J1_DOWN_Pin|IR_SENSOR3_Pin|IR_SENSOR4_Pin|IR_SENSOR5_LEFT_Pin;
  GPIO_InitStruct.Mode = GPIO_MODE_INPUT;
  GPIO_InitStruct.Pull = GPIO_NOPULL;
  HAL_GPIO_Init(GPIOE, &GPIO_InitStruct);

  /*Configure GPIO pins : SPI4_CS_Pin PWM2_PIN1_Pin PWM2_PIN2_Pin */
  GPIO_InitStruct.Pin = SPI4_CS_Pin|PWM2_PIN1_Pin|PWM2_PIN2_Pin;
  GPIO_InitStruct.Mode = GPIO_MODE_OUTPUT_PP;
  GPIO_InitStruct.Pull = GPIO_NOPULL;
  GPIO_InitStruct.Speed = GPIO_SPEED_FREQ_LOW;
  HAL_GPIO_Init(GPIOE, &GPIO_InitStruct);

  /*Configure GPIO pin : USER_Btn_Pin */
  GPIO_InitStruct.Pin = USER_Btn_Pin;
  GPIO_InitStruct.Mode = GPIO_MODE_IT_RISING;
  GPIO_InitStruct.Pull = GPIO_NOPULL;
  HAL_GPIO_Init(USER_Btn_GPIO_Port, &GPIO_InitStruct);

  /*Configure GPIO pins : SW2_Pin SW6_Pin */
  GPIO_InitStruct.Pin = SW2_Pin|SW6_Pin;
  GPIO_InitStruct.Mode = GPIO_MODE_INPUT;
  GPIO_InitStruct.Pull = GPIO_NOPULL;
  HAL_GPIO_Init(GPIOF, &GPIO_InitStruct);

  /*Configure GPIO pins : SW7_Pin SW8_Pin SW9_Boost_Zuun_Dood_Pin IR_SENSOR1_Pin */
  GPIO_InitStruct.Pin = SW7_Pin|SW8_Pin|SW9_Boost_Zuun_Dood_Pin|IR_SENSOR1_Pin;
  GPIO_InitStruct.Mode = GPIO_MODE_INPUT;
  GPIO_InitStruct.Pull = GPIO_NOPULL;
  HAL_GPIO_Init(GPIOC, &GPIO_InitStruct);

  /*Configure GPIO pin : SW10_Boost_Zuun_Deed_Pin */
  GPIO_InitStruct.Pin = SW10_Boost_Zuun_Deed_Pin;
  GPIO_InitStruct.Mode = GPIO_MODE_INPUT;
  GPIO_InitStruct.Pull = GPIO_NOPULL;
  HAL_GPIO_Init(SW10_Boost_Zuun_Deed_GPIO_Port, &GPIO_InitStruct);

  /*Configure GPIO pins : LD1_Pin RELAY6_Pin LD3_Pin RELAY5_Pin
                           LD2_Pin */
  GPIO_InitStruct.Pin = LD1_Pin|RELAY6_Pin|LD3_Pin|RELAY5_Pin
                          |LD2_Pin;
  GPIO_InitStruct.Mode = GPIO_MODE_OUTPUT_PP;
  GPIO_InitStruct.Pull = GPIO_NOPULL;
  GPIO_InitStruct.Speed = GPIO_SPEED_FREQ_LOW;
  HAL_GPIO_Init(GPIOB, &GPIO_InitStruct);

  /*Configure GPIO pins : SW5_Pin SW11_Boost_Baruun_Deed_Pin SW12_Boost_Baruun_Dood_Pin IR_SENSOR6_RIGHT_Pin */
  GPIO_InitStruct.Pin = SW5_Pin|SW11_Boost_Baruun_Deed_Pin|SW12_Boost_Baruun_Dood_Pin|IR_SENSOR6_RIGHT_Pin;
  GPIO_InitStruct.Mode = GPIO_MODE_INPUT;
  GPIO_InitStruct.Pull = GPIO_NOPULL;
  HAL_GPIO_Init(GPIOG, &GPIO_InitStruct);

  /*Configure GPIO pin : PE7 */
  GPIO_InitStruct.Pin = GPIO_PIN_7;
  GPIO_InitStruct.Mode = GPIO_MODE_AF_PP;
  GPIO_InitStruct.Pull = GPIO_NOPULL;
  GPIO_InitStruct.Speed = GPIO_SPEED_FREQ_VERY_HIGH;
  GPIO_InitStruct.Alternate = GPIO_AF8_UART7;
  HAL_GPIO_Init(GPIOE, &GPIO_InitStruct);

  /*Configure GPIO pins : RELAY1_Pin RELAY4_Pin RELAY3_Pin MAX485_DE_RE_Pin */
  GPIO_InitStruct.Pin = RELAY1_Pin|RELAY4_Pin|RELAY3_Pin|MAX485_DE_RE_Pin;
  GPIO_InitStruct.Mode = GPIO_MODE_OUTPUT_PP;
  GPIO_InitStruct.Pull = GPIO_NOPULL;
  GPIO_InitStruct.Speed = GPIO_SPEED_FREQ_LOW;
  HAL_GPIO_Init(GPIOD, &GPIO_InitStruct);

  /*Configure GPIO pins : IR_SENSOR2_Pin SW4_J2_UP_Pin SW3_J2_DOWN_Pin IR_SENSOR7_BACK_Pin
                           IR_SENSOR8_BOX_DETECTION_Pin */
  GPIO_InitStruct.Pin = IR_SENSOR2_Pin|SW4_J2_UP_Pin|SW3_J2_DOWN_Pin|IR_SENSOR7_BACK_Pin
                          |IR_SENSOR8_BOX_DETECTION_Pin;
  GPIO_InitStruct.Mode = GPIO_MODE_INPUT;
  GPIO_InitStruct.Pull = GPIO_NOPULL;
  HAL_GPIO_Init(GPIOD, &GPIO_InitStruct);

  /*Configure GPIO pins : SPI5_CS_Pin RELAY2_Pin PWM1_PIN2_Pin PWM1_PIN1_Pin */
  GPIO_InitStruct.Pin = SPI5_CS_Pin|RELAY2_Pin|PWM1_PIN2_Pin|PWM1_PIN1_Pin;
  GPIO_InitStruct.Mode = GPIO_MODE_OUTPUT_PP;
  GPIO_InitStruct.Pull = GPIO_NOPULL;
  GPIO_InitStruct.Speed = GPIO_SPEED_FREQ_LOW;
  HAL_GPIO_Init(GPIOG, &GPIO_InitStruct);

  /*Configure GPIO pins : RS485_RE_Pin RS485_DE_Pin */
  GPIO_InitStruct.Pin = RS485_RE_Pin|RS485_DE_Pin;
  GPIO_InitStruct.Mode = GPIO_MODE_OUTPUT_PP;
  GPIO_InitStruct.Pull = GPIO_NOPULL;
  GPIO_InitStruct.Speed = GPIO_SPEED_FREQ_VERY_HIGH;
  HAL_GPIO_Init(GPIOG, &GPIO_InitStruct);

  /*Configure GPIO pin : SPI3_CS_Pin */
  GPIO_InitStruct.Pin = SPI3_CS_Pin;
  GPIO_InitStruct.Mode = GPIO_MODE_OUTPUT_PP;
  GPIO_InitStruct.Pull = GPIO_NOPULL;
  GPIO_InitStruct.Speed = GPIO_SPEED_FREQ_LOW;
  HAL_GPIO_Init(SPI3_CS_GPIO_Port, &GPIO_InitStruct);

}

void HAL_TIM_PeriodElapsedCallback(TIM_HandleTypeDef *htim)
{
  if (htim->Instance == TIM7)
  {
    HAL_IncTick();
  }
}

void Error_Handler(void)
{
	__disable_irq();
	while (1)
	{
	}
}
